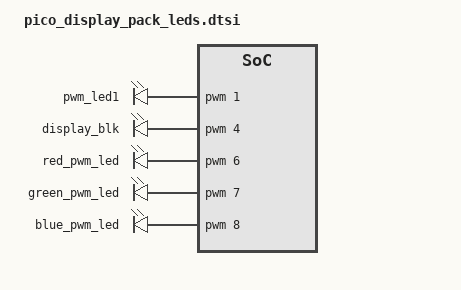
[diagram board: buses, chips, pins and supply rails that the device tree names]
/ {
    pwm_leds {
        compatible = "pwm-leds";
        status = "okay";

        pwm_led1: pwm_led_1 {
            pwms = <&pwm 1 PWM_MSEC(20) PWM_POLARITY_NORMAL>;
        };

        display_blk: pwm_led_0 {
            pwms = <&pwm 4 PWM_MSEC(20) PWM_POLARITY_NORMAL>;
        };

        red_pwm_led: red_pwm_led {
            pwms = <&pwm 6 PWM_MSEC(20) PWM_POLARITY_INVERTED>;
        };

        green_pwm_led: green_pwm_led {
            pwms = <&pwm 7 PWM_MSEC(20) PWM_POLARITY_INVERTED>;
        };

        blue_pwm_led: blue_pwm_led {
            pwms = <&pwm 8 PWM_MSEC(20) PWM_POLARITY_INVERTED>;
        };
    };
};
